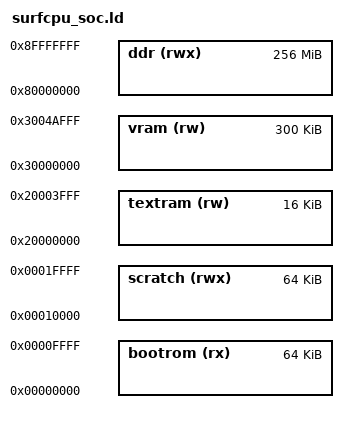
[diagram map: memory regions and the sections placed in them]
/*
 * Generated from spec/soc.toml by tools/socspec.py gen -- do not edit.
 * SurfCPU memory map version 2, SoC version 0.4.0.
 */

/* Symbols for every region, reservation and hole; INCLUDE this before SECTIONS. */
SURF_BOOTROM_BASE = 0x00000000;
SURF_BOOTROM_SIZE = 0x00010000;
SURF_SCRATCH_BASE = 0x00010000;
SURF_SCRATCH_SIZE = 0x00010000;
SURF_UART_BASE = 0x10000000;
SURF_UART_SIZE = 0x00001000;
SURF_TIMER_BASE = 0x10001000;
SURF_TIMER_SIZE = 0x00001000;
SURF_INTC_BASE = 0x10002000;
SURF_INTC_SIZE = 0x00001000;
SURF_GPIO_BASE = 0x10003000;
SURF_GPIO_SIZE = 0x00001000;
SURF_SPI_BASE = 0x10004000;
SURF_SPI_SIZE = 0x00001000;
SURF_PS2_BASE = 0x10005000;
SURF_PS2_SIZE = 0x00001000;
SURF_VIDEO_BASE = 0x10006000;
SURF_VIDEO_SIZE = 0x00001000;
SURF_SYSINFO_BASE = 0x10007000;
SURF_SYSINFO_SIZE = 0x00001000;
SURF_ETH_BASE = 0x10008000;
SURF_ETH_SIZE = 0x00001000;
SURF_GPU_BASE = 0x10009000;
SURF_GPU_SIZE = 0x00001000;
SURF_DDRC_BASE = 0x1000A000;
SURF_DDRC_SIZE = 0x00002000;
SURF_TEXTRAM_BASE = 0x20000000;
SURF_TEXTRAM_SIZE = 0x00004000;
SURF_VRAM_BASE = 0x30000000;
SURF_VRAM_SIZE = 0x00080000;
SURF_DDR_BASE = 0x80000000;
SURF_DDR_SIZE = 0x10000000;
SURF_SURFBOOT_DATA_BASE = 0x00010000;
SURF_SURFBOOT_DATA_SIZE = 0x0000F000;
SURF_BOOTINFO_BASE = 0x0001F000;
SURF_BOOTINFO_SIZE = 0x00001000;
SURF_KERNEL_BASE = 0x80000000;
SURF_KERNEL_SIZE = 0x0F000000;
SURF_DDR_TOP_BASE = 0x8F000000;
SURF_DDR_TOP_SIZE = 0x01000000;
SURF_UNMAPPED_PROBE_BASE = 0x40000000;
SURF_UNMAPPED_PROBE_SIZE = 0x10000000;

/* a memory region is as long as the memory in it (bytes), not its decoded window */
MEMORY
{
  bootrom  (rx ) : ORIGIN = 0x00000000, LENGTH = 0x00010000
  scratch  (rwx) : ORIGIN = 0x00010000, LENGTH = 0x00010000
  textram  (rw ) : ORIGIN = 0x20000000, LENGTH = 0x00004000
  vram     (rw ) : ORIGIN = 0x30000000, LENGTH = 0x0004B000
  ddr      (rwx) : ORIGIN = 0x80000000, LENGTH = 0x10000000
}
